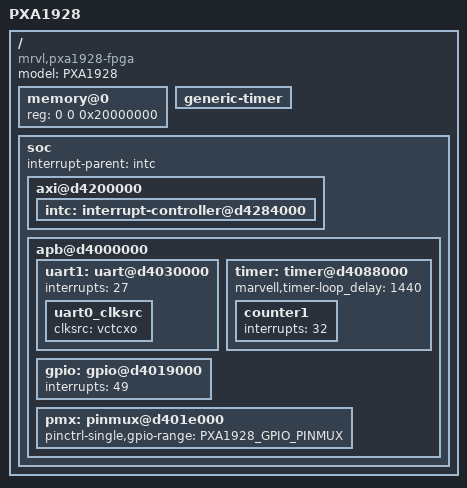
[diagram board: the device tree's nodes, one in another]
/*
 * PXA1928 FPGA Board
 */

/dts-v1/;
#include "pxa1928.dtsi"

/ {
	model = "PXA1928";
	compatible = "mrvl,pxa1928-fpga", "mrvl,pxa1928";

	memory@0 {
		device_type = "memory";
		reg = <0 0 0x20000000>;
	};

	generic-timer {
		status = "okay";
	};

	soc {
		interrupt-parent = <&intc>;
		axi@d4200000 {
			intc: interrupt-controller@d4284000 {
				status = "okay";
			};
		};

		apb@d4000000 {
			uart1: uart@d4030000 {
				interrupts = <27>;
				status = "okay";

				uart0_clksrc {
					clksrc = "vctcxo";
				};
			};

			timer: timer@d4088000 {
				marvell,timer-loop_delay = <1440>;

				counter1 {
					interrupts = <32>;
				};
			};

			gpio: gpio@d4019000 {
				interrupts = <49>;
				status = "okay";
			};

			pmx: pinmux@d401e000 {
				status = "okay";
				/* pin base, nr pins & gpio function */
				pinctrl-single,gpio-range = <PXA1928_GPIO_PINMUX>;
			};
		};
	};
};
